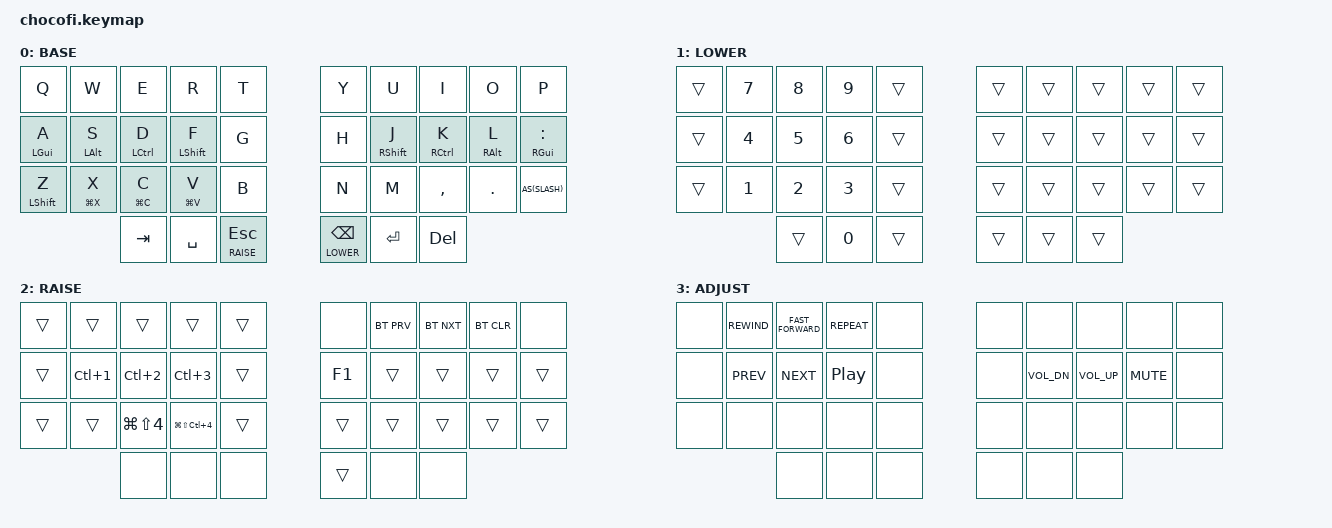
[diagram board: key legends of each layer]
#include <behaviors.dtsi>
#include <dt-bindings/zmk/keys.h>
#include <dt-bindings/zmk/bt.h>

#define BASE 0
#define LOWER  1
#define RAISE  2
#define ADJUST  3// macros definition
#define undo LC(Z)
#define redo LC(LS(Z))
#define cycle_layout LA(LS(SPACE))
#define move_focus LA(LS(K))
#define WS1 &kp LC(N1)
#define WS2 &kp LC(N2)
#define WS3 &kp LC(N3)
#define SS1 &kp LG(LS(LC(N4)))
#define SS2 &kp LG(LS(N4))
#define deg RA(LS(SEMI))// tune mod tap
#define AS(keycode) &as LS(keycode) keycode     // Autoshift Macro

&mt {
    flavor = "tap-preferred";
    tapping_term_ms = <200>;
};

// caps word settings

&caps_word {
    continue-list = <UNDERSCORE MINUS N1 N2 N3 N4 N5 N6 N7 N8 N9 N0>;
};

// main tree

/ {
    conditional_layers {
        compatible = "zmk,conditional-layers";
        tri_layer {
            if-layers = <RAISE LOWER>;
            then-layer = <ADJUST>;
        };
    };

    behaviors {
        // HOME ROW MODS

        hml: left_hand_positional_hold_tap {
            compatible = "zmk,behavior-hold-tap";
            label = "LEFT_POSITIONAL_HOLD_TAP";
            #binding-cells = <2>;
            flavor = "balanced";
            tapping-term-ms = <280>;
            quick-tap-ms = <175>;
            bindings =
                <&kp>,
                <&kp>;

            hold-trigger-key-positions = <5 6 7 8 9 15 16 17 18 19 25 26 27 28 29 33 34 35>;// <---[[right-hand keys]]
            hold-trigger-on-release;
        };
        hmr: right_hand_positional_hold_tap {
            compatible = "zmk,behavior-hold-tap";
            label = "RIGHT_POSITIONAL_HOLD_TAP";
            #binding-cells = <2>;
            flavor = "balanced";
            tapping-term-ms = <200>;
            quick-tap-ms = <175>;
            bindings =
                <&kp>,
                <&kp>;

            hold-trigger-key-positions = <0 1 2 3 4 10 11 12 13 14 20 21 22 23 24 30 31 32>;// <---[[right-hand keys]]
            hold-trigger-on-release;
        };
        mo_kp: behavior_mo_kp {
            compatible = "zmk,behavior-hold-tap";
            label = "mo_kp";
            #binding-cells = <2>;
            flavor = "hold-preferred";
            tapping-term-ms = <300>;
            quick-tap-ms = <200>;
            bindings = <&mo>, <&kp>;
        };
        as: auto_shift {
            compatible = "zmk,behavior-hold-tap";
            label = "AUTO_SHIFT";
            #binding-cells = <2>;
            tapping_term_ms = <135>;
            quick_tap_ms = <0>;
            flavor = "tap-preferred";
            bindings = <&kp>, <&kp>;
        };
        osm: one_shot_mods {
            compatible = "zmk,behavior-hold-tap";
            label = "ONE_SHOT_MODS";
            #binding-cells = <2>;
            tapping-term-ms = <300>;// <---[[moderate duration]]
            quick-tap-ms = <0>;
            flavor = "balanced";
            bindings =
                <&sk>,
                <&kp>;
        };

        // TAP DANCES

        spacetab: tap_dance_space_tab {
            compatible = "zmk,behavior-tap-dance";
            label = "TAP_DANCE_SPACE_TAB";
            #binding-cells = <0>;
            tapping-term-ms = <175>;
            bindings =
                <&kp SPACE>,
                <&kp TAB>;
        };
        grvtilde: tap_dance_grave_tilde {
            compatible = "zmk,behavior-tap-dance";
            label = "TAP_DANCE_GRAVE_TILDE";
            #binding-cells = <0>;
            tapping-term-ms = <300>;
            bindings =
                <&kp GRAVE>,
                <&kp TILDE>;
        };
        apoquote: tap_dance_apostrophe_quote {
            compatible = "zmk,behavior-tap-dance";
            label = "TAP_DANCE_APOSTROPE_QUOTE";
            #binding-cells = <0>;
            tapping-term-ms = <300>;
            bindings =
                <&kp SQT>,
                <&kp DQT>;
        };
        eurodollar: tap_dance_euro_dollar {
            compatible = "zmk,behavior-tap-dance";
            label = "TAP_DANCE_EURO_DOLLAR";
            #binding-cells = <0>;
            tapping-term-ms = <300>;
            bindings =
                <&kp RA(N5)>,
                <&kp DLLR>;
        };
        close: tap_dance_close {
            compatible = "zmk,behavior-tap-dance";
            label = "TAP_DANCE_CLOSE";
            #binding-cells = <0>;
            tapping-term-ms = <300>;
            bindings =
                <&kp LC(F4)>,
                <&kp LA(F4)>;
        };
    };

    // macros https://zmk.dev/docs/behaviors/macros

    macros {
        find_file: find_file {
            label = "FUZZY_FIND_FILE";
            compatible = "zmk,behavior-macro";
            #binding-cells = <0>;
            bindings = <&macro_tap &kp SPACE &kp F &kp F>;
        };
        grep_file: grep_file {
            label = "FUZZY_GREP_FILE";
            compatible = "zmk,behavior-macro";
            #binding-cells = <0>;
            bindings = <&macro_tap &kp SPACE &kp F &kp G>;
        };
        buffered_file: buffered_file {
            label = "FUZZY_BUFFERED_FILE";
            compatible = "zmk,behavior-macro";
            #binding-cells = <0>;
            bindings = <&macro_tap &kp SPACE &kp F &kp B>;
        };
    };

    // combos https://zmk.dev/docs/features/combos

    combos {
        compatible = "zmk,combos";

        combo_grave {
            bindings = <AS(GRAVE)>;
            key-positions = <0 10>;
        };

        combo_lpar {
            bindings = <&kp LPAR>;
            key-positions = <1 11>;
        };

        combo_lbkt {
            bindings = <AS(LBKT)>;
            key-positions = <2 12>;
        };

        combo_rbkt {
            bindings = <AS(RBKT)>;
            key-positions = <3 13>;
        };

        combo_rpar {
            bindings = <&kp RPAR>;
            key-positions = <4 14>;
        };

        combo_left {
            bindings = <&kp LEFT>;
            key-positions = <5 15>;
        };

        combo_down {
            bindings = <&kp DOWN>;
            key-positions = <6 16>;
        };

        combo_up {
            bindings = <&kp UP>;
            key-positions = <7 17>;
        };


        combo_right {
            bindings = <&kp RIGHT>;
            key-positions = <8 18>;
        };

        combo_backslash {
            bindings = <AS(BACKSLASH)>;
            key-positions = <9 19>;
        };

        combo_excl {
            bindings = <&kp EXCL>;
            key-positions = <10 20>;
        };

        combo_at {
            bindings = <&kp AT>;
            key-positions = <11 21>;
        };

        combo_caret {
            bindings = <&kp CARET>;
            key-positions = <12 22>;
        };

        combo_minus {
            bindings = <AS(MINUS)>;
            key-positions = <13 23>;
        };

        combo_dollar {
            bindings = <&kp DOLLAR>;
            key-positions = <14 24>;
        };

        combo_equal {
            bindings = <AS(EQL)>;
            key-positions = <15 25>;
        };

        combo_percent {
            bindings = <&kp PERCENT>;
            key-positions = <16 26>;
        };

        combo_star {
            bindings = <&kp STAR>;
            key-positions = <17 27>;
        };

        combo_amps {
            bindings = <&kp AMPS>;
            key-positions = <18 28>;
        };

        combo_hash {
            bindings = <&kp HASH>;
            key-positions = <19 29>;
        };

        combo_capword {
            bindings = <&caps_word>;
            key-positions = <13 16>;
        };

        combo_apos {
            bindings = <AS(APOS)>;
            key-positions = <18 19>;
        };

         combo_semi {
            bindings = <&kp SEMI>;
            key-positions = <28 29>;
        };
    };

    keymap {
        compatible = "zmk,keymap";

        default_layer {
            label = "BASE";
            bindings = <
  &kp Q            &kp W           &kp E            &kp R           &kp T              &kp Y     &kp U            &kp I           &kp O        &kp P
  &hml LEFT_GUI A  &hml LALT S     &hml LCTRL D     &hml LSHIFT F   &kp G              &kp H     &hmr RSHIFT J    &hmr RCTRL K    &hmr RALT L  &hmr RIGHT_GUI COLON
  &hml LSHIFT Z    &hml LG(X) X    &hml LG(C) C     &hml LG(V) V    &kp B              &kp N     &kp M            &kp COMMA       &kp DOT      AS(SLASH)
                                   &kp TAB          &kp SPACE       &lt RAISE ESC      &mo_kp LOWER BACKSPACE     &kp ENTER       &kp DEL
            >;
        };

        lower_layer {
            label = "LOWER";
            bindings = <
  &trans   &kp N7     &kp N8     &kp N9     &trans     &trans &trans &trans &trans &trans
  &trans   &kp N4     &kp N5     &kp N6     &trans     &trans &trans &trans &trans &trans
  &trans   &kp N1     &kp N2     &kp N3     &trans     &trans &trans &trans &trans &trans
              &trans     &kp N0     &trans             &trans &trans &trans
            >;
        };

        raise_layer {
            label = "RAISE";
            bindings = <
  &trans  &trans    &trans    &trans  &trans       &none         &bt BT_PRV     &bt BT_NXT     &bt BT_CLR   &none
  &trans  WS1       WS2       WS3     &trans       &kp F1        &trans         &trans         &trans       &trans
  &trans  &trans    SS2       SS1     &trans       &trans        &trans         &trans         &trans       &trans
                        &none     &none   &none    &trans        &none      &none
            >;
        };

        adjust_layer {
            label = "ADJUST";
            bindings = <
  &none  &kp C_REWIND  &kp C_FAST_FORWARD  &kp C_REPEAT      &none         &none     &none          &none          &none        &none
  &none  &kp C_PREV    &kp C_NEXT          &kp C_PLAY_PAUSE  &none         &none     &kp C_VOL_DN   &kp C_VOL_UP   &kp C_MUTE   &none
  &none  &none         &none               &none             &none         &none     &none          &none          &none        &none
                       &none               &none             &none         &none     &none          &none
            >;
        };
    };
};
